AUTOSAR XML (schema 4-2-2)
package /STELLANTIS/EPT/ASWCs
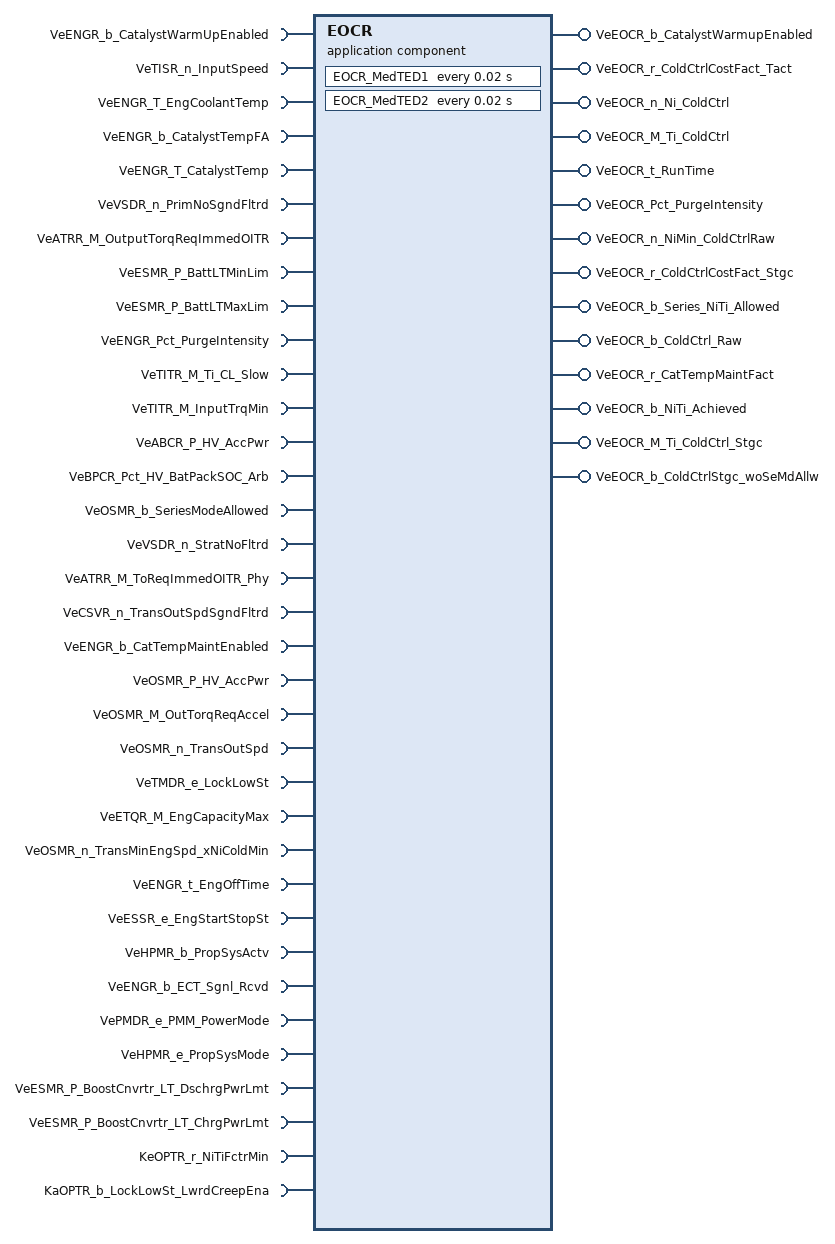
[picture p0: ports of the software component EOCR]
  application sw component type EOCR
    33 x require port:
      VeENGR_b_CatalystWarmUpEnabled: nonqueued-receiver-com-spec{data-element=Value, init-value=0}, required-interface=VeENGR_b_CatalystWarmUpEnabled
      VeTISR_n_InputSpeed: nonqueued-receiver-com-spec{data-element=Value, init-value=0}, required-interface=VeTISR_n_InputSpeed
      VeENGR_T_EngCoolantTemp: nonqueued-receiver-com-spec{data-element=Value, init-value=0}, required-interface=VeENGR_T_EngCoolantTemp
      VeENGR_b_CatalystTempFA: nonqueued-receiver-com-spec{data-element=Value, init-value=0}, required-interface=VeENGR_b_CatalystTempFA
      VeENGR_T_CatalystTemp: nonqueued-receiver-com-spec{data-element=Value, init-value=0}, required-interface=VeENGR_T_CatalystTemp
      VeVSDR_n_PrimNoSgndFltrd: nonqueued-receiver-com-spec{data-element=Value, init-value=0}, required-interface=VeVSDR_n_PrimNoSgndFltrd
      VeATRR_M_OutputTorqReqImmedOITR: nonqueued-receiver-com-spec{data-element=Value, init-value=0}, required-interface=VeATRR_M_OutputTorqReqImmedOITR
      VeESMR_P_BattLTMinLim: nonqueued-receiver-com-spec{data-element=Value, init-value=0}, required-interface=VeESMR_P_BattLTMinLim
      VeESMR_P_BattLTMaxLim: nonqueued-receiver-com-spec{data-element=Value, init-value=0}, required-interface=VeESMR_P_BattLTMaxLim
      VeENGR_Pct_PurgeIntensity: nonqueued-receiver-com-spec{data-element=Value, init-value=0}, required-interface=VeENGR_Pct_PurgeIntensity
      VeTITR_M_Ti_CL_Slow: nonqueued-receiver-com-spec{data-element=Value, init-value=0}, required-interface=VeTITR_M_Ti_CL_Slow
      VeTITR_M_InputTrqMin: nonqueued-receiver-com-spec{data-element=Value, init-value=0}, required-interface=VeTITR_M_InputTrqMin
      VeABCR_P_HV_AccPwr: nonqueued-receiver-com-spec{data-element=Value, init-value=0}, required-interface=VeABCR_P_HV_AccPwr
      VeBPCR_Pct_HV_BatPackSOC_Arb: nonqueued-receiver-com-spec{data-element=Value, init-value=0}, required-interface=VeBPCR_Pct_HV_BatPackSOC_Arb
      VeOSMR_b_SeriesModeAllowed: nonqueued-receiver-com-spec{data-element=Value, init-value=0}, required-interface=VeOSMR_b_SeriesModeAllowed
      VeVSDR_n_StratNoFltrd: nonqueued-receiver-com-spec{data-element=Value, init-value=0}, required-interface=VeVSDR_n_StratNoFltrd
      VeATRR_M_ToReqImmedOITR_Phy: nonqueued-receiver-com-spec{data-element=Value, init-value=0}, required-interface=VeATRR_M_ToReqImmedOITR_Phy
      VeCSVR_n_TransOutSpdSgndFltrd: nonqueued-receiver-com-spec{data-element=Value, init-value=0}, required-interface=VeCSVR_n_TransOutSpdSgndFltrd
      VeENGR_b_CatTempMaintEnabled: nonqueued-receiver-com-spec{data-element=Value, init-value=0}, required-interface=VeENGR_b_CatTempMaintEnabled
      VeOSMR_P_HV_AccPwr: nonqueued-receiver-com-spec{data-element=Value, init-value=0}, required-interface=VeOSMR_P_HV_AccPwr
      VeOSMR_M_OutTorqReqAccel: nonqueued-receiver-com-spec{data-element=Value, init-value=0}, required-interface=VeOSMR_M_OutTorqReqAccel
      VeOSMR_n_TransOutSpd: nonqueued-receiver-com-spec{data-element=Value, init-value=0}, required-interface=VeOSMR_n_TransOutSpd
      VeTMDR_e_LockLowSt: nonqueued-receiver-com-spec{data-element=Value, init-value=CeTMDR_e_Off}, required-interface=VeTMDR_e_LockLowSt
      VeETQR_M_EngCapacityMax: nonqueued-receiver-com-spec{data-element=Value, init-value=0}, required-interface=VeETQR_M_EngCapacityMax
      VeOSMR_n_TransMinEngSpd_xNiColdMin: nonqueued-receiver-com-spec{data-element=Value, init-value=0}, required-interface=VeOSMR_n_TransMinEngSpd_xNiColdMin
      VeENGR_t_EngOffTime: nonqueued-receiver-com-spec{data-element=Value, init-value=0}, required-interface=VeENGR_t_EngOffTime
      VeESSR_e_EngStartStopSt: nonqueued-receiver-com-spec{data-element=Value, init-value=CeESSR_e_EngOff}, required-interface=VeESSR_e_EngStartStopSt
      VeHPMR_b_PropSysActv: nonqueued-receiver-com-spec{data-element=Value, init-value=0}, required-interface=VeHPMR_b_PropSysActv
      VeENGR_b_ECT_Sgnl_Rcvd: nonqueued-receiver-com-spec{data-element=Value, init-value=0}, required-interface=VeENGR_b_ECT_Sgnl_Rcvd
      VePMDR_e_PMM_PowerMode: nonqueued-receiver-com-spec{data-element=Value, init-value=CePMDR_e_PowerMode_Off}, required-interface=VePMDR_e_PMM_PowerMode
      VeHPMR_e_PropSysMode: nonqueued-receiver-com-spec{data-element=Value, init-value=CeHPMR_e_Disabled}, required-interface=VeHPMR_e_PropSysMode
      VeESMR_P_BoostCnvrtr_LT_DschrgPwrLmt: nonqueued-receiver-com-spec{data-element=Value, init-value=0}, required-interface=VeESMR_P_BoostCnvrtr_LT_DschrgPwrLmt
      VeESMR_P_BoostCnvrtr_LT_ChrgPwrLmt: nonqueued-receiver-com-spec{data-element=Value, init-value=0}, required-interface=VeESMR_P_BoostCnvrtr_LT_ChrgPwrLmt
    14 x provide port, all with nonqueued-sender-com-spec{data-element=Value, init-value=0}:
      VeEOCR_b_CatalystWarmupEnabled: provided-interface=VeEOCR_b_CatalystWarmupEnabled
      VeEOCR_r_ColdCtrlCostFact_Tact: provided-interface=VeEOCR_r_ColdCtrlCostFact_Tact
      VeEOCR_n_Ni_ColdCtrl: provided-interface=VeEOCR_n_Ni_ColdCtrl
      VeEOCR_M_Ti_ColdCtrl: provided-interface=VeEOCR_M_Ti_ColdCtrl
      VeEOCR_t_RunTime: provided-interface=VeEOCR_t_RunTime
      VeEOCR_Pct_PurgeIntensity: provided-interface=VeEOCR_Pct_PurgeIntensity
      VeEOCR_n_NiMin_ColdCtrlRaw: provided-interface=VeEOCR_n_NiMin_ColdCtrlRaw
      VeEOCR_r_ColdCtrlCostFact_Stgc: provided-interface=VeEOCR_r_ColdCtrlCostFact_Stgc
      VeEOCR_b_Series_NiTi_Allowed: provided-interface=VeEOCR_b_Series_NiTi_Allowed
      VeEOCR_b_ColdCtrl_Raw: provided-interface=VeEOCR_b_ColdCtrl_Raw
      VeEOCR_r_CatTempMaintFact: provided-interface=VeEOCR_r_CatTempMaintFact
      VeEOCR_b_NiTi_Achieved: provided-interface=VeEOCR_b_NiTi_Achieved
      VeEOCR_M_Ti_ColdCtrl_Stgc: provided-interface=VeEOCR_M_Ti_ColdCtrl_Stgc
      VeEOCR_b_ColdCtrlStgc_woSeMdAllw: provided-interface=VeEOCR_b_ColdCtrlStgc_woSeMdAllw
    require port KeOPTR_r_NiTiFctrMin: parameter-require-com-spec{init-value=KeOPTR_r_NiTiFctrMin_KeOPTR_r_NiTiFctrMin:0.00999999977648258, parameter=KeOPTR_r_NiTiFctrMin}, required-interface=KeOPTR_r_NiTiFctrMin
    require port KaOPTR_b_LockLowSt_LwrdCreepEna: parameter-require-com-spec{init-value=KaOPTR_b_LockLowSt_LwrdCreepEna_KaOPTR_b_LockLowSt_LwrdCreepEna:[KaOPTR_b_LockLowSt_LwrdCreepEna_KaOPTR_b_LockLowSt_LwrdCreepEna_rt_Array_Boolean_3_1:0, KaOPTR_b_LockLowSt_LwrdCreepEna_KaOPTR_b_LockLowSt_LwrdCreepEna_rt_Array_Boolean_3_2:0, KaOPTR_b_LockLowSt_LwrdCreepEna_KaOPTR_b_LockLowSt_LwrdCreepEna_rt_Array_Boolean_3_3:1], parameter=KaOPTR_b_LockLowSt_LwrdCreepEna}, required-interface=KaOPTR_b_LockLowSt_LwrdCreepEna
    behavior IB_EOCR: data-type-mapping=msADTtoIDTMapping, handle-termination-and-restart=NO-SUPPORT
      timing event Event_MedTED1: start-on-event=EOCR_MedTED1, period=0.02
      timing event Event_MedTED2: start-on-event=EOCR_MedTED2, period=0.02
      init event Event_EOCR_ac_Init: start-on-event=EOCR_ac_Init
      init event Event_PwrOn: start-on-event=EOCR_PwrOn
      explicit-inter-runnable-variables:
        6 x data, all with category=VALUE, sw-calibration-access=READ-ONLY, init-value=0:
          CTMEnabled_write_IRV: type=Boolean
          LeEOCR_n_Ni_ColdCtrl_Old_write_IRV: type=Float
          LeEOCR_M_Ti_ColdCtrl_Old_write_IRV: type=Float
          EngSpd_write_IRV: type=Float
          VeEOCC_r_TactMultwoPwrDlt_write_IRV: type=Float
          ColdCtrlStgc_woSeMdAllw_toCalcB_write_IRV: type=Boolean
      4 x runnable:
        EOCR_ac_Init
        EOCR_PwrOn
          data-send-points:
            14 x access:
              OUT_VeEOCR_r_CatTempMaintFact_Value: accessed-variable=VeEOCR_r_CatTempMaintFact.Value
              OUT_VeEOCR_b_CatalystWarmupEnabled_Value: accessed-variable=VeEOCR_b_CatalystWarmupEnabled.Value
              OUT_VeEOCR_r_ColdCtrlCostFact_Stgc_Value: accessed-variable=VeEOCR_r_ColdCtrlCostFact_Stgc.Value
              OUT_VeEOCR_r_ColdCtrlCostFact_Tact_Value: accessed-variable=VeEOCR_r_ColdCtrlCostFact_Tact.Value
              OUT_VeEOCR_b_ColdCtrl_Raw_Value: accessed-variable=VeEOCR_b_ColdCtrl_Raw.Value
              OUT_VeEOCR_b_ColdCtrlStgc_woSeMdAllw_Value: accessed-variable=VeEOCR_b_ColdCtrlStgc_woSeMdAllw.Value
              OUT_VeEOCR_n_Ni_ColdCtrl_Value: accessed-variable=VeEOCR_n_Ni_ColdCtrl.Value
              OUT_VeEOCR_n_NiMin_ColdCtrlRaw_Value: accessed-variable=VeEOCR_n_NiMin_ColdCtrlRaw.Value
              OUT_VeEOCR_Pct_PurgeIntensity_Value: accessed-variable=VeEOCR_Pct_PurgeIntensity.Value
              OUT_VeEOCR_t_RunTime_Value: accessed-variable=VeEOCR_t_RunTime.Value
              OUT_VeEOCR_b_Series_NiTi_Allowed_Value: accessed-variable=VeEOCR_b_Series_NiTi_Allowed.Value
              OUT_VeEOCR_M_Ti_ColdCtrl_Value: accessed-variable=VeEOCR_M_Ti_ColdCtrl.Value
              OUT_VeEOCR_M_Ti_ColdCtrl_Stgc_Value: accessed-variable=VeEOCR_M_Ti_ColdCtrl_Stgc.Value
              OUT_VeEOCR_b_NiTi_Achieved_Value: accessed-variable=VeEOCR_b_NiTi_Achieved.Value
          written-local-variables:
            6 x access:
              WV_CTMEnabled_write_IRV: accessed-variable=CTMEnabled_write_IRV
              WV_ColdCtrlStgc_woSeMdAllw_toCalcB_write_IRV: accessed-variable=ColdCtrlStgc_woSeMdAllw_toCalcB_write_IRV
              WV_EngSpd_write_IRV: accessed-variable=EngSpd_write_IRV
              WV_LeEOCR_M_Ti_ColdCtrl_Old_write_IRV: accessed-variable=LeEOCR_M_Ti_ColdCtrl_Old_write_IRV
              WV_LeEOCR_n_Ni_ColdCtrl_Old_write_IRV: accessed-variable=LeEOCR_n_Ni_ColdCtrl_Old_write_IRV
              WV_VeEOCC_r_TactMultwoPwrDlt_write_IRV: accessed-variable=VeEOCC_r_TactMultwoPwrDlt_write_IRV
        EOCR_MedTED1
          data-receive-point-by-arguments:
            21 x access:
              IN_VeABCR_P_HV_AccPwr_Value: accessed-variable=VeABCR_P_HV_AccPwr.Value
              IN_VeATRR_M_ToReqImmedOITR_Phy_Value: accessed-variable=VeATRR_M_ToReqImmedOITR_Phy.Value
              IN_VeBPCR_Pct_HV_BatPackSOC_Arb_Value: accessed-variable=VeBPCR_Pct_HV_BatPackSOC_Arb.Value
              IN_VeCSVR_n_TransOutSpdSgndFltrd_Value: accessed-variable=VeCSVR_n_TransOutSpdSgndFltrd.Value
              IN_VeENGR_Pct_PurgeIntensity_Value: accessed-variable=VeENGR_Pct_PurgeIntensity.Value
              IN_VeENGR_T_CatalystTemp_Value: accessed-variable=VeENGR_T_CatalystTemp.Value
              IN_VeENGR_T_EngCoolantTemp_Value: accessed-variable=VeENGR_T_EngCoolantTemp.Value
              IN_VeENGR_b_CatTempMaintEnabled_Value: accessed-variable=VeENGR_b_CatTempMaintEnabled.Value
              IN_VeENGR_b_CatalystTempFA_Value: accessed-variable=VeENGR_b_CatalystTempFA.Value
              IN_VeENGR_b_CatalystWarmUpEnabled_Value: accessed-variable=VeENGR_b_CatalystWarmUpEnabled.Value
              IN_VeENGR_b_ECT_Sgnl_Rcvd_Value: accessed-variable=VeENGR_b_ECT_Sgnl_Rcvd.Value
              IN_VeENGR_t_EngOffTime_Value: accessed-variable=VeENGR_t_EngOffTime.Value
              IN_VeESMR_P_BattLTMaxLim_Value: accessed-variable=VeESMR_P_BattLTMaxLim.Value
              IN_VeESMR_P_BoostCnvrtr_LT_DschrgPwrLmt_Value: accessed-variable=VeESMR_P_BoostCnvrtr_LT_DschrgPwrLmt.Value
              IN_VeESSR_e_EngStartStopSt_Value: accessed-variable=VeESSR_e_EngStartStopSt.Value
              IN_VeHPMR_b_PropSysActv_Value: accessed-variable=VeHPMR_b_PropSysActv.Value
              IN_VeHPMR_e_PropSysMode_Value: accessed-variable=VeHPMR_e_PropSysMode.Value
              IN_VePMDR_e_PMM_PowerMode_Value: accessed-variable=VePMDR_e_PMM_PowerMode.Value
              IN_VeTISR_n_InputSpeed_Value: accessed-variable=VeTISR_n_InputSpeed.Value
              IN_VeVSDR_n_PrimNoSgndFltrd_Value: accessed-variable=VeVSDR_n_PrimNoSgndFltrd.Value
              IN_VeVSDR_n_StratNoFltrd_Value: accessed-variable=VeVSDR_n_StratNoFltrd.Value
          data-send-points:
            6 x access:
              OUT_VeEOCR_b_CatalystWarmupEnabled_Value: accessed-variable=VeEOCR_b_CatalystWarmupEnabled.Value
              OUT_VeEOCR_b_ColdCtrl_Raw_Value: accessed-variable=VeEOCR_b_ColdCtrl_Raw.Value
              OUT_VeEOCR_b_ColdCtrlStgc_woSeMdAllw_Value: accessed-variable=VeEOCR_b_ColdCtrlStgc_woSeMdAllw.Value
              OUT_VeEOCR_n_NiMin_ColdCtrlRaw_Value: accessed-variable=VeEOCR_n_NiMin_ColdCtrlRaw.Value
              OUT_VeEOCR_Pct_PurgeIntensity_Value: accessed-variable=VeEOCR_Pct_PurgeIntensity.Value
              OUT_VeEOCR_t_RunTime_Value: accessed-variable=VeEOCR_t_RunTime.Value
          parameter access CALPRM_KeOPTR_r_NiTiFctrMin_KeOPTR_r_NiTiFctrMin: accessed-parameter=KeOPTR_r_NiTiFctrMin.KeOPTR_r_NiTiFctrMin
          written-local-variables:
            6 x access:
              WV_CTMEnabled_write_IRV: accessed-variable=CTMEnabled_write_IRV
              WV_ColdCtrlStgc_woSeMdAllw_toCalcB_write_IRV: accessed-variable=ColdCtrlStgc_woSeMdAllw_toCalcB_write_IRV
              WV_EngSpd_write_IRV: accessed-variable=EngSpd_write_IRV
              WV_LeEOCR_M_Ti_ColdCtrl_Old_write_IRV: accessed-variable=LeEOCR_M_Ti_ColdCtrl_Old_write_IRV
              WV_LeEOCR_n_Ni_ColdCtrl_Old_write_IRV: accessed-variable=LeEOCR_n_Ni_ColdCtrl_Old_write_IRV
              WV_VeEOCC_r_TactMultwoPwrDlt_write_IRV: accessed-variable=VeEOCC_r_TactMultwoPwrDlt_write_IRV
        EOCR_MedTED2
          data-receive-point-by-arguments:
            19 x access:
              IN_VeABCR_P_HV_AccPwr_Value: accessed-variable=VeABCR_P_HV_AccPwr.Value
              IN_VeATRR_M_OutputTorqReqImmedOITR_Value: accessed-variable=VeATRR_M_OutputTorqReqImmedOITR.Value
              IN_VeATRR_M_ToReqImmedOITR_Phy_Value: accessed-variable=VeATRR_M_ToReqImmedOITR_Phy.Value
              IN_VeBPCR_Pct_HV_BatPackSOC_Arb_Value: accessed-variable=VeBPCR_Pct_HV_BatPackSOC_Arb.Value
              IN_VeCSVR_n_TransOutSpdSgndFltrd_Value: accessed-variable=VeCSVR_n_TransOutSpdSgndFltrd.Value
              IN_VeESMR_P_BattLTMaxLim_Value: accessed-variable=VeESMR_P_BattLTMaxLim.Value
              IN_VeESMR_P_BattLTMinLim_Value: accessed-variable=VeESMR_P_BattLTMinLim.Value
              IN_VeESMR_P_BoostCnvrtr_LT_ChrgPwrLmt_Value: accessed-variable=VeESMR_P_BoostCnvrtr_LT_ChrgPwrLmt.Value
              IN_VeESMR_P_BoostCnvrtr_LT_DschrgPwrLmt_Value: accessed-variable=VeESMR_P_BoostCnvrtr_LT_DschrgPwrLmt.Value
              IN_VeETQR_M_EngCapacityMax_Value: accessed-variable=VeETQR_M_EngCapacityMax.Value
              IN_VeOSMR_M_OutTorqReqAccel_Value: accessed-variable=VeOSMR_M_OutTorqReqAccel.Value
              IN_VeOSMR_P_HV_AccPwr_Value: accessed-variable=VeOSMR_P_HV_AccPwr.Value
              IN_VeOSMR_b_SeriesModeAllowed_Value: accessed-variable=VeOSMR_b_SeriesModeAllowed.Value
              IN_VeOSMR_n_TransMinEngSpd_xNiColdMin_Value: accessed-variable=VeOSMR_n_TransMinEngSpd_xNiColdMin.Value
              IN_VeOSMR_n_TransOutSpd_Value: accessed-variable=VeOSMR_n_TransOutSpd.Value
              IN_VeTITR_M_InputTrqMin_Value: accessed-variable=VeTITR_M_InputTrqMin.Value
              IN_VeTITR_M_Ti_CL_Slow_Value: accessed-variable=VeTITR_M_Ti_CL_Slow.Value
              IN_VeTMDR_e_LockLowSt_Value: accessed-variable=VeTMDR_e_LockLowSt.Value
              IN_VeVSDR_n_PrimNoSgndFltrd_Value: accessed-variable=VeVSDR_n_PrimNoSgndFltrd.Value
          data-send-points:
            7 x access:
              OUT_VeEOCR_r_CatTempMaintFact_Value: accessed-variable=VeEOCR_r_CatTempMaintFact.Value
              OUT_VeEOCR_r_ColdCtrlCostFact_Stgc_Value: accessed-variable=VeEOCR_r_ColdCtrlCostFact_Stgc.Value
              OUT_VeEOCR_r_ColdCtrlCostFact_Tact_Value: accessed-variable=VeEOCR_r_ColdCtrlCostFact_Tact.Value
              OUT_VeEOCR_n_Ni_ColdCtrl_Value: accessed-variable=VeEOCR_n_Ni_ColdCtrl.Value
              OUT_VeEOCR_b_Series_NiTi_Allowed_Value: accessed-variable=VeEOCR_b_Series_NiTi_Allowed.Value
              OUT_VeEOCR_M_Ti_ColdCtrl_Value: accessed-variable=VeEOCR_M_Ti_ColdCtrl.Value
              OUT_VeEOCR_M_Ti_ColdCtrl_Stgc_Value: accessed-variable=VeEOCR_M_Ti_ColdCtrl_Stgc.Value
          parameter access CALPRM_KaOPTR_b_LockLowSt_LwrdCreepEna_KaOPTR_b_LockLowSt_LwrdCreepEna: accessed-parameter=KaOPTR_b_LockLowSt_LwrdCreepEna.KaOPTR_b_LockLowSt_LwrdCreepEna
          parameter access CALPRM_KeOPTR_r_NiTiFctrMin_KeOPTR_r_NiTiFctrMin: accessed-parameter=KeOPTR_r_NiTiFctrMin.KeOPTR_r_NiTiFctrMin
          read-local-variables:
            6 x access:
              RV_CTMEnabled_write_IRV: accessed-variable=CTMEnabled_write_IRV
              RV_ColdCtrlStgc_woSeMdAllw_toCalcB_write_IRV: accessed-variable=ColdCtrlStgc_woSeMdAllw_toCalcB_write_IRV
              RV_EngSpd_write_IRV: accessed-variable=EngSpd_write_IRV
              RV_LeEOCR_M_Ti_ColdCtrl_Old_write_IRV: accessed-variable=LeEOCR_M_Ti_ColdCtrl_Old_write_IRV
              RV_LeEOCR_n_Ni_ColdCtrl_Old_write_IRV: accessed-variable=LeEOCR_n_Ni_ColdCtrl_Old_write_IRV
              RV_VeEOCC_r_TactMultwoPwrDlt_write_IRV: accessed-variable=VeEOCC_r_TactMultwoPwrDlt_write_IRV
      4 x variation point proxy, all with category=CONDITION:
        Variant_EOCR_1: condition-access=1
        Variant_EOCR_2: condition-access=0
        Variant_EOCR_3: condition-access=0
        Variant_EOCR_4: condition-access=1
